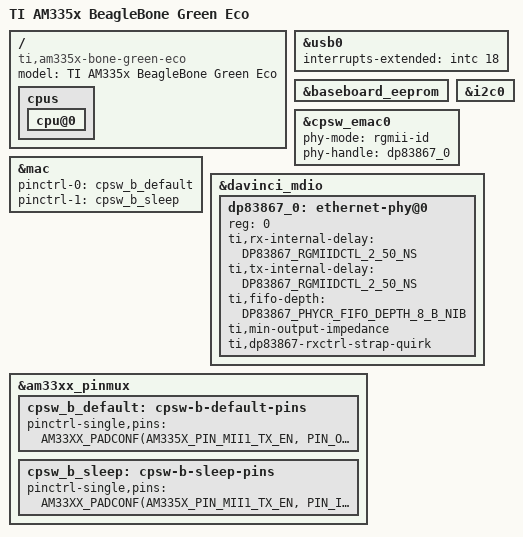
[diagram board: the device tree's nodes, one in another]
// SPDX-License-Identifier: GPL-2.0-only
/*
 * Copyright (C) 2025 Bootlin
 */
/dts-v1/;

#include "am33xx.dtsi"
#include "am335x-bone-common.dtsi"
#include "am335x-bonegreen-common.dtsi"
#include <dt-bindings/net/ti-dp83867.h>

/ {
	model = "TI AM335x BeagleBone Green Eco";
	compatible = "ti,am335x-bone-green-eco", "ti,am335x-bone-green",
		     "ti,am335x-bone-black", "ti,am335x-bone", "ti,am33xx";

	cpus {
		cpu@0 {
			/delete-property/ cpu0-supply;
		};
	};
};

&usb0 {
	interrupts-extended = <&intc 18>;
	interrupt-names = "mc";
};

&baseboard_eeprom {
	/delete-property/ vcc-supply;
};

&i2c0 {
	/delete-node/ tps@24;
};

&cpsw_emac0 {
	phy-mode = "rgmii-id";
	phy-handle = <&dp83867_0>;
};

&mac {
	pinctrl-0 = <&cpsw_b_default>;
	pinctrl-1 = <&cpsw_b_sleep>;
};

&davinci_mdio {
	/delete-node/ ethernet-phy@0;

	dp83867_0: ethernet-phy@0 {
		reg = <0>;
		ti,rx-internal-delay = <DP83867_RGMIIDCTL_2_50_NS>;
		ti,tx-internal-delay = <DP83867_RGMIIDCTL_2_50_NS>;
		ti,fifo-depth = <DP83867_PHYCR_FIFO_DEPTH_8_B_NIB>;
		ti,min-output-impedance;
		ti,dp83867-rxctrl-strap-quirk;
	};
};

&am33xx_pinmux {
	cpsw_b_default: cpsw-b-default-pins {
		pinctrl-single,pins = <
			AM33XX_PADCONF(AM335X_PIN_MII1_TX_EN, PIN_OUTPUT_PULLDOWN, MUX_MODE2)
			AM33XX_PADCONF(AM335X_PIN_MII1_RX_DV, PIN_INPUT_PULLDOWN, MUX_MODE2)
			AM33XX_PADCONF(AM335X_PIN_MII1_TX_CLK, PIN_OUTPUT_PULLDOWN, MUX_MODE2)
			AM33XX_PADCONF(AM335X_PIN_MII1_RX_CLK, PIN_INPUT_PULLDOWN, MUX_MODE2)
			AM33XX_PADCONF(AM335X_PIN_MII1_TXD0, PIN_OUTPUT_PULLDOWN, MUX_MODE2)
			AM33XX_PADCONF(AM335X_PIN_MII1_TXD1, PIN_OUTPUT_PULLDOWN, MUX_MODE2)
			AM33XX_PADCONF(AM335X_PIN_MII1_TXD2, PIN_OUTPUT_PULLDOWN, MUX_MODE2)
			AM33XX_PADCONF(AM335X_PIN_MII1_TXD3, PIN_OUTPUT_PULLDOWN, MUX_MODE2)
			AM33XX_PADCONF(AM335X_PIN_MII1_RXD0, PIN_INPUT_PULLDOWN, MUX_MODE2)
			AM33XX_PADCONF(AM335X_PIN_MII1_RXD1, PIN_INPUT_PULLDOWN, MUX_MODE2)
			AM33XX_PADCONF(AM335X_PIN_MII1_RXD2, PIN_INPUT_PULLDOWN, MUX_MODE2)
			AM33XX_PADCONF(AM335X_PIN_MII1_RXD3, PIN_INPUT_PULLDOWN, MUX_MODE2)
		>;
	};

	cpsw_b_sleep: cpsw-b-sleep-pins {
		pinctrl-single,pins = <
			AM33XX_PADCONF(AM335X_PIN_MII1_TX_EN, PIN_INPUT_PULLDOWN, MUX_MODE7)
			AM33XX_PADCONF(AM335X_PIN_MII1_RX_DV, PIN_INPUT_PULLDOWN, MUX_MODE7)
			AM33XX_PADCONF(AM335X_PIN_MII1_TX_CLK, PIN_INPUT_PULLDOWN, MUX_MODE7)
			AM33XX_PADCONF(AM335X_PIN_MII1_RX_CLK, PIN_INPUT_PULLDOWN, MUX_MODE7)
			AM33XX_PADCONF(AM335X_PIN_MII1_TXD0, PIN_INPUT_PULLDOWN, MUX_MODE7)
			AM33XX_PADCONF(AM335X_PIN_MII1_TXD1, PIN_INPUT_PULLDOWN, MUX_MODE7)
			AM33XX_PADCONF(AM335X_PIN_MII1_TXD2, PIN_INPUT_PULLDOWN, MUX_MODE7)
			AM33XX_PADCONF(AM335X_PIN_MII1_TXD3, PIN_INPUT_PULLDOWN, MUX_MODE7)
			AM33XX_PADCONF(AM335X_PIN_MII1_RXD0, PIN_INPUT_PULLDOWN, MUX_MODE7)
			AM33XX_PADCONF(AM335X_PIN_MII1_RXD1, PIN_INPUT_PULLDOWN, MUX_MODE7)
			AM33XX_PADCONF(AM335X_PIN_MII1_RXD2, PIN_INPUT_PULLDOWN, MUX_MODE7)
			AM33XX_PADCONF(AM335X_PIN_MII1_RXD3, PIN_INPUT_PULLDOWN, MUX_MODE7)
		>;
	};
};
